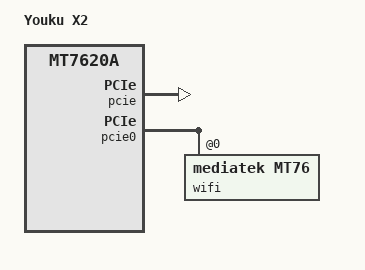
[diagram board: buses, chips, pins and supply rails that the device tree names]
// SPDX-License-Identifier: GPL-2.0-or-later OR MIT

#include "mt7620a_youku_yk-l1.dtsi"

/ {
	compatible = "youku,x2", "ralink,mt7620a-soc";
	model = "Youku X2";
};

&ethernet {
	mediatek,portmap = "wllll";
};

&firmware {
	reg = <0x50000 0xfb0000>;
};

&led_wlan {
	linux,default-trigger = "phy1tpt";
};

&pcie {
	status = "okay";
};

&pcie0 {
	wifi@0,0 {
		compatible = "mediatek,mt76";
		reg = <0x0000 0 0 0 0>;
		mediatek,mtd-eeprom = <&factory 0x8000>;
		ieee80211-freq-limit = <5000000 6000000>;

		led {
			led-sources = <2>;
			led-active-low;
		};
	};
};
